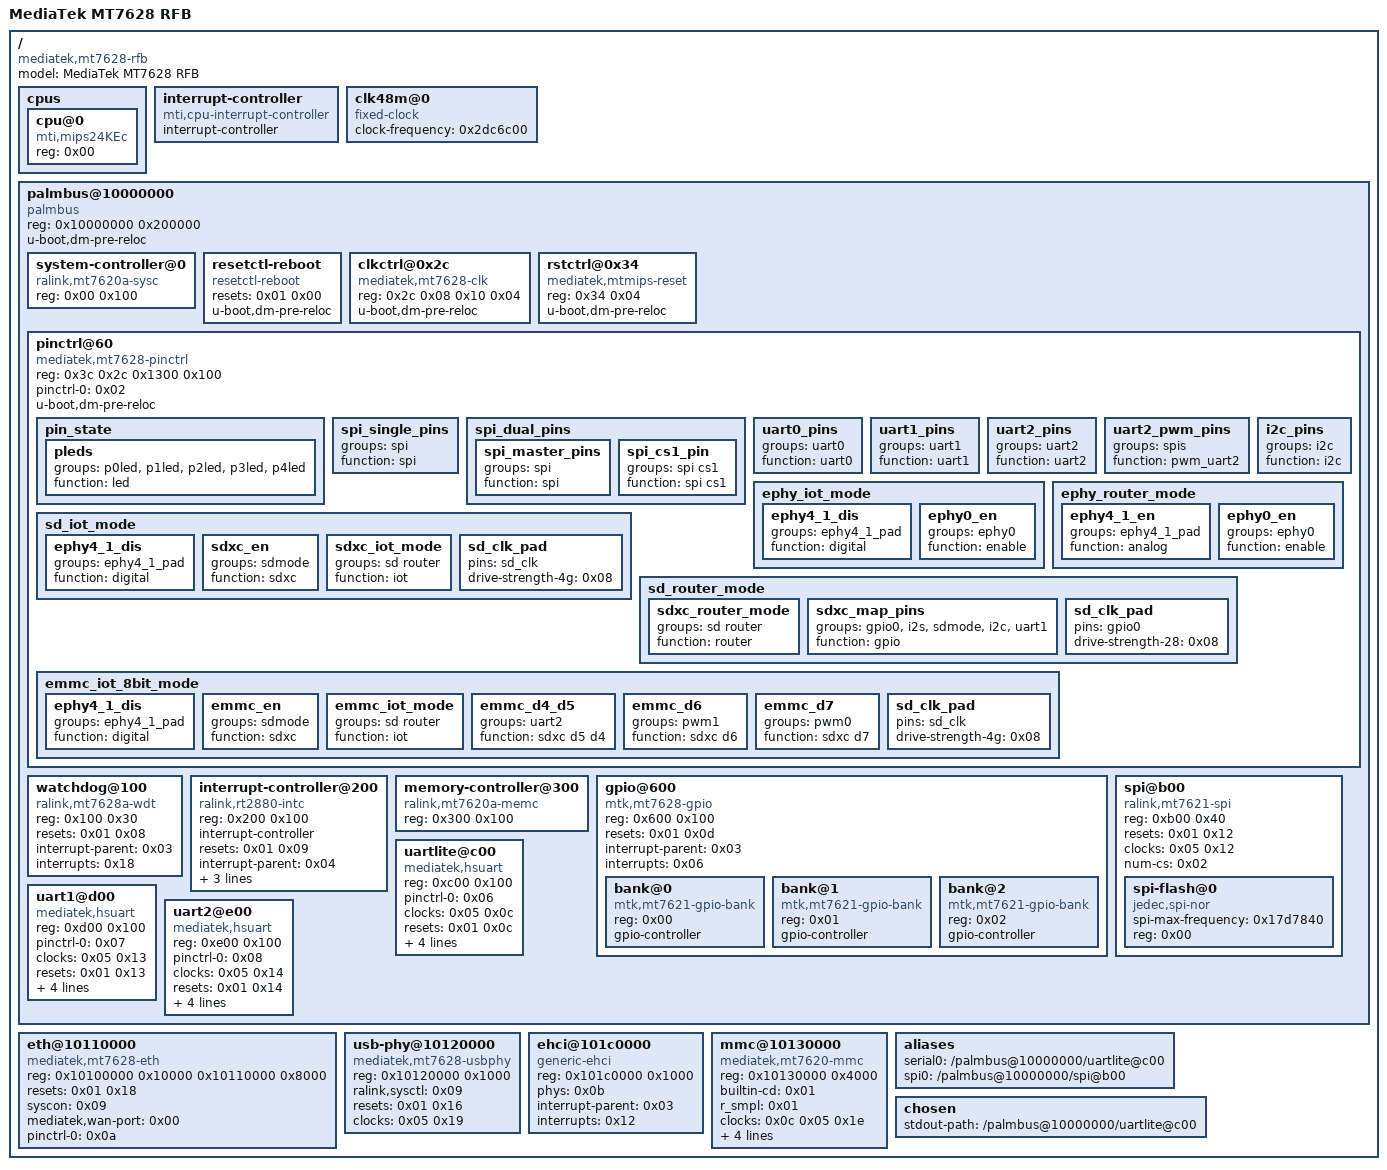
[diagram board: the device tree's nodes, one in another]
/dts-v1/;

/ {
	#address-cells = <0x01>;
	#size-cells = <0x01>;
	compatible = "mediatek,mt7628-rfb", "ralink,mt7628a-soc";
	model = "MediaTek MT7628 RFB";

	cpus {
		#address-cells = <0x01>;
		#size-cells = <0x00>;

		cpu@0 {
			compatible = "mti,mips24KEc";
			device_type = "cpu";
			reg = <0x00>;
		};
	};

	interrupt-controller {
		#address-cells = <0x00>;
		#interrupt-cells = <0x01>;
		interrupt-controller;
		compatible = "mti,cpu-interrupt-controller";
		phandle = <0x04>;
	};

	clk48m@0 {
		compatible = "fixed-clock";
		clock-frequency = <0x2dc6c00>;
		#clock-cells = <0x00>;
		phandle = <0x0c>;
	};

	palmbus@10000000 {
		compatible = "palmbus", "simple-bus";
		reg = <0x10000000 0x200000>;
		ranges = <0x00 0x10000000 0x1fffff>;
		#address-cells = <0x01>;
		#size-cells = <0x01>;
		u-boot,dm-pre-reloc;

		system-controller@0 {
			compatible = "ralink,mt7620a-sysc", "syscon";
			reg = <0x00 0x100>;
			phandle = <0x09>;
		};

		resetctl-reboot {
			compatible = "resetctl-reboot";
			resets = <0x01 0x00>;
			reset-names = "sysreset";
			u-boot,dm-pre-reloc;
		};

		clkctrl@0x2c {
			reg = <0x2c 0x08 0x10 0x04>;
			reg-names = "syscfg0", "clkcfg";
			compatible = "mediatek,mt7628-clk";
			#clock-cells = <0x01>;
			u-boot,dm-pre-reloc;
			phandle = <0x05>;
		};

		rstctrl@0x34 {
			reg = <0x34 0x04>;
			compatible = "mediatek,mtmips-reset";
			#reset-cells = <0x01>;
			u-boot,dm-pre-reloc;
			phandle = <0x01>;
		};

		pinctrl@60 {
			compatible = "mediatek,mt7628-pinctrl";
			reg = <0x3c 0x2c 0x1300 0x100>;
			reg-names = "gpiomode", "padconf";
			pinctrl-names = "default";
			pinctrl-0 = <0x02>;
			u-boot,dm-pre-reloc;

			pin_state {
				phandle = <0x02>;

				pleds {
					groups = "p0led", "p1led", "p2led", "p3led", "p4led";
					function = "led";
				};
			};

			spi_single_pins {
				groups = "spi";
				function = "spi";
			};

			spi_dual_pins {

				spi_master_pins {
					groups = "spi";
					function = "spi";
				};

				spi_cs1_pin {
					groups = "spi cs1";
					function = "spi cs1";
				};
			};

			uart0_pins {
				groups = "uart0";
				function = "uart0";
				phandle = <0x06>;
			};

			uart1_pins {
				groups = "uart1";
				function = "uart1";
				phandle = <0x07>;
			};

			uart2_pins {
				groups = "uart2";
				function = "uart2";
				phandle = <0x08>;
			};

			uart2_pwm_pins {
				groups = "spis";
				function = "pwm_uart2";
			};

			i2c_pins {
				groups = "i2c";
				function = "i2c";
			};

			ephy_iot_mode {

				ephy4_1_dis {
					groups = "ephy4_1_pad";
					function = "digital";
				};

				ephy0_en {
					groups = "ephy0";
					function = "enable";
				};
			};

			ephy_router_mode {
				phandle = <0x0a>;

				ephy4_1_en {
					groups = "ephy4_1_pad";
					function = "analog";
				};

				ephy0_en {
					groups = "ephy0";
					function = "enable";
				};
			};

			sd_iot_mode {

				ephy4_1_dis {
					groups = "ephy4_1_pad";
					function = "digital";
				};

				sdxc_en {
					groups = "sdmode";
					function = "sdxc";
				};

				sdxc_iot_mode {
					groups = "sd router";
					function = "iot";
				};

				sd_clk_pad {
					pins = "sd_clk";
					drive-strength-4g = <0x08>;
				};
			};

			sd_router_mode {
				phandle = <0x0d>;

				sdxc_router_mode {
					groups = "sd router";
					function = "router";
				};

				sdxc_map_pins {
					groups = "gpio0", "i2s", "sdmode", "i2c", "uart1";
					function = "gpio";
				};

				sd_clk_pad {
					pins = "gpio0";
					drive-strength-28 = <0x08>;
				};
			};

			emmc_iot_8bit_mode {

				ephy4_1_dis {
					groups = "ephy4_1_pad";
					function = "digital";
				};

				emmc_en {
					groups = "sdmode";
					function = "sdxc";
				};

				emmc_iot_mode {
					groups = "sd router";
					function = "iot";
				};

				emmc_d4_d5 {
					groups = "uart2";
					function = "sdxc d5 d4";
				};

				emmc_d6 {
					groups = "pwm1";
					function = "sdxc d6";
				};

				emmc_d7 {
					groups = "pwm0";
					function = "sdxc d7";
				};

				sd_clk_pad {
					pins = "sd_clk";
					drive-strength-4g = <0x08>;
				};
			};
		};

		watchdog@100 {
			compatible = "ralink,mt7628a-wdt", "mediatek,mt7621-wdt";
			reg = <0x100 0x30>;
			resets = <0x01 0x08>;
			reset-names = "wdt";
			interrupt-parent = <0x03>;
			interrupts = <0x18>;
		};

		interrupt-controller@200 {
			compatible = "ralink,rt2880-intc";
			reg = <0x200 0x100>;
			interrupt-controller;
			#interrupt-cells = <0x01>;
			resets = <0x01 0x09>;
			reset-names = "intc";
			interrupt-parent = <0x04>;
			interrupts = <0x02>;
			ralink,intc-registers = <0x9c 0xa0 0x6c 0xa4 0x80 0x78>;
			phandle = <0x03>;
		};

		memory-controller@300 {
			compatible = "ralink,mt7620a-memc";
			reg = <0x300 0x100>;
		};

		gpio@600 {
			#address-cells = <0x01>;
			#size-cells = <0x00>;
			compatible = "mtk,mt7628-gpio", "mtk,mt7621-gpio";
			reg = <0x600 0x100>;
			resets = <0x01 0x0d>;
			reset-names = "pio";
			interrupt-parent = <0x03>;
			interrupts = <0x06>;

			bank@0 {
				reg = <0x00>;
				compatible = "mtk,mt7621-gpio-bank";
				gpio-controller;
				#gpio-cells = <0x02>;
			};

			bank@1 {
				reg = <0x01>;
				compatible = "mtk,mt7621-gpio-bank";
				gpio-controller;
				#gpio-cells = <0x02>;
			};

			bank@2 {
				reg = <0x02>;
				compatible = "mtk,mt7621-gpio-bank";
				gpio-controller;
				#gpio-cells = <0x02>;
			};
		};

		spi@b00 {
			compatible = "ralink,mt7621-spi";
			reg = <0xb00 0x40>;
			resets = <0x01 0x12>;
			reset-names = "spi";
			#address-cells = <0x01>;
			#size-cells = <0x00>;
			clocks = <0x05 0x12>;
			status = "okay";
			num-cs = <0x02>;

			spi-flash@0 {
				#address-cells = <0x01>;
				#size-cells = <0x01>;
				compatible = "jedec,spi-nor";
				spi-max-frequency = <0x17d7840>;
				reg = <0x00>;
			};
		};

		uartlite@c00 {
			compatible = "mediatek,hsuart", "ns16550a";
			reg = <0xc00 0x100>;
			pinctrl-names = "default";
			pinctrl-0 = <0x06>;
			clocks = <0x05 0x0c>;
			resets = <0x01 0x0c>;
			reset-names = "uart0";
			interrupt-parent = <0x03>;
			interrupts = <0x14>;
			reg-shift = <0x02>;
			status = "okay";
			u-boot,dm-pre-reloc;
		};

		uart1@d00 {
			compatible = "mediatek,hsuart", "ns16550a";
			reg = <0xd00 0x100>;
			pinctrl-names = "default";
			pinctrl-0 = <0x07>;
			clocks = <0x05 0x13>;
			resets = <0x01 0x13>;
			reset-names = "uart1";
			interrupt-parent = <0x03>;
			interrupts = <0x15>;
			reg-shift = <0x02>;
			u-boot,dm-pre-reloc;
		};

		uart2@e00 {
			compatible = "mediatek,hsuart", "ns16550a";
			reg = <0xe00 0x100>;
			pinctrl-names = "default";
			pinctrl-0 = <0x08>;
			clocks = <0x05 0x14>;
			resets = <0x01 0x14>;
			reset-names = "uart2";
			interrupt-parent = <0x03>;
			interrupts = <0x16>;
			reg-shift = <0x02>;
			u-boot,dm-pre-reloc;
		};
	};

	eth@10110000 {
		compatible = "mediatek,mt7628-eth";
		reg = <0x10100000 0x10000 0x10110000 0x8000>;
		resets = <0x01 0x18>;
		reset-names = "ephy";
		syscon = <0x09>;
		mediatek,wan-port = <0x00>;
		pinctrl-names = "default";
		pinctrl-0 = <0x0a>;
	};

	usb-phy@10120000 {
		compatible = "mediatek,mt7628-usbphy";
		reg = <0x10120000 0x1000>;
		#phy-cells = <0x00>;
		ralink,sysctl = <0x09>;
		resets = <0x01 0x16>;
		reset-names = "phy";
		clocks = <0x05 0x19>;
		clock-names = "cg";
		phandle = <0x0b>;
	};

	ehci@101c0000 {
		compatible = "generic-ehci";
		reg = <0x101c0000 0x1000>;
		phys = <0x0b>;
		phy-names = "usb";
		interrupt-parent = <0x03>;
		interrupts = <0x12>;
	};

	mmc@10130000 {
		compatible = "mediatek,mt7620-mmc";
		reg = <0x10130000 0x4000>;
		builtin-cd = <0x01>;
		r_smpl = <0x01>;
		clocks = <0x0c 0x05 0x1e>;
		clock-names = "source", "hclk";
		resets = <0x01 0x1e>;
		status = "okay";
		bus-width = <0x04>;
		cap-sd-highspeed;
		pinctrl-names = "default";
		pinctrl-0 = <0x0d>;
	};

	aliases {
		serial0 = "/palmbus@10000000/uartlite@c00";
		spi0 = "/palmbus@10000000/spi@b00";
	};

	chosen {
		stdout-path = "/palmbus@10000000/uartlite@c00";
	};
};
